AUTOSAR XML (schema 4-0-3)
standard types defined: Boolean, UInt16, UInt32, UInt8
package /AUTOSAR_Platform/DataConstrs
  range DC_Boolean: raw 0..1
  range DC_UInt16: raw 0..65535
  range DC_UInt8: raw 0..255
package /PATAC/MSM/ComponentTypes
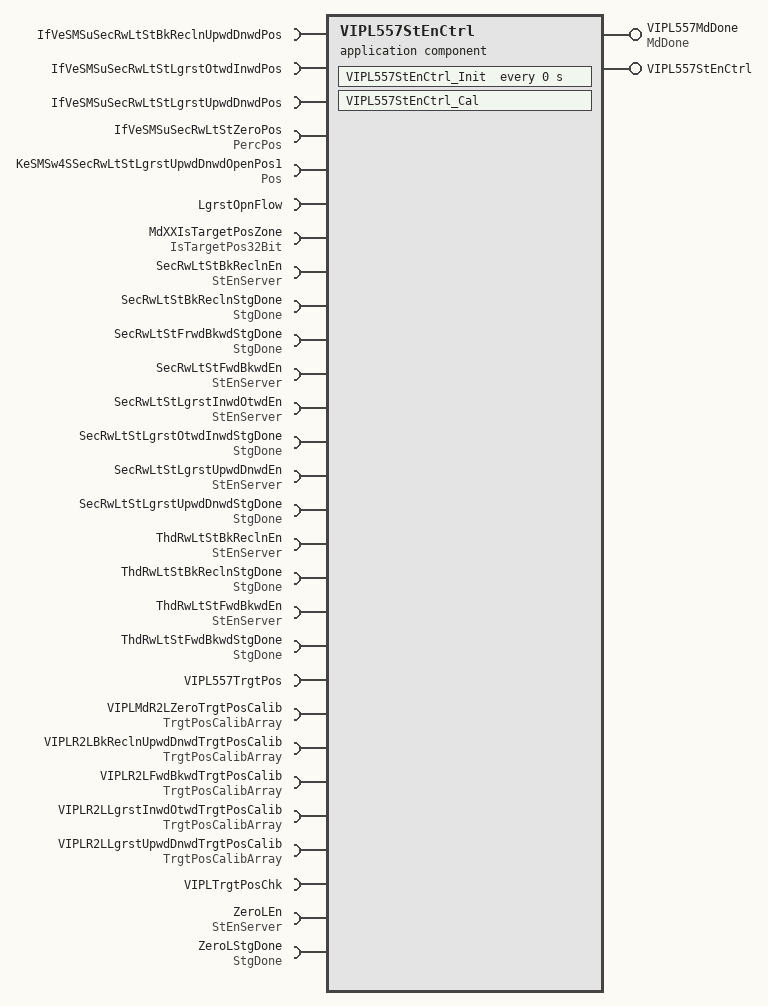
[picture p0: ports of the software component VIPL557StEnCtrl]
  application sw component type VIPL557StEnCtrl
    provide port VIPL557MdDone: nonqueued-sender-com-spec{data-element=MdDone/Val, init-value=0}, provided-interface=MdDone
    provide port VIPL557StEnCtrl: server-com-spec{operation=VIPL557StEnCtrl/Cal, queue-length=1}, provided-interface=VIPL557StEnCtrl
    28 x require port:
      IfVeSMSuSecRwLtStBkReclnUpwdDnwdPos: nonqueued-receiver-com-spec{data-element=IfVeSMSuSecRwLtStBkReclnUpwdDnwdPos/Val, filter=data-filter-type=ALWAYS, init-value=0}, required-interface=IfVeSMSuSecRwLtStBkReclnUpwdDnwdPos
      IfVeSMSuSecRwLtStLgrstOtwdInwdPos: nonqueued-receiver-com-spec{data-element=IfVeSMSuSecRwLtStLgrstOtwdInwdPos/Val, filter=data-filter-type=ALWAYS, init-value=0}, required-interface=IfVeSMSuSecRwLtStLgrstOtwdInwdPos
      IfVeSMSuSecRwLtStLgrstUpwdDnwdPos: nonqueued-receiver-com-spec{data-element=IfVeSMSuSecRwLtStLgrstUpwdDnwdPos/Val, filter=data-filter-type=ALWAYS, init-value=0}, required-interface=IfVeSMSuSecRwLtStLgrstUpwdDnwdPos
      IfVeSMSuSecRwLtStZeroPos: nonqueued-receiver-com-spec{data-element=PercPos/Val, filter=data-filter-type=ALWAYS, init-value=0}, required-interface=PercPos
      KeSMSw4SSecRwLtStLgrstUpwdDnwdOpenPos1: parameter-require-com-spec{init-value=0, parameter=Val}, required-interface=Pos
      LgrstOpnFlow: client-com-spec=LgrstOpnFlow/Cal, required-interface=LgrstOpnFlow
      MdXXIsTargetPosZone: nonqueued-receiver-com-spec{data-element=IsTargetPos32Bit/Val, filter=data-filter-type=ALWAYS, init-value=0}, required-interface=IsTargetPos32Bit
      SecRwLtStBkReclnEn: required-com-specs=[Clear, StEnServer/Get, StEnServer/Set], required-interface=StEnServer
      SecRwLtStBkReclnStgDone: nonqueued-receiver-com-spec{data-element=StgDone/Val, filter=data-filter-type=ALWAYS, init-value=0}, required-interface=StgDone
      SecRwLtStFrwdBkwdStgDone: nonqueued-receiver-com-spec{data-element=StgDone/Val, filter=data-filter-type=ALWAYS, init-value=0}, required-interface=StgDone
      SecRwLtStFwdBkwdEn: required-com-specs=[Clear, StEnServer/Get, StEnServer/Set], required-interface=StEnServer
      SecRwLtStLgrstInwdOtwdEn: required-com-specs=[Clear, StEnServer/Get, StEnServer/Set], required-interface=StEnServer
      SecRwLtStLgrstOtwdInwdStgDone: nonqueued-receiver-com-spec{data-element=StgDone/Val, filter=data-filter-type=ALWAYS, init-value=0}, required-interface=StgDone
      SecRwLtStLgrstUpwdDnwdEn: required-com-specs=[Clear, StEnServer/Get, StEnServer/Set], required-interface=StEnServer
      SecRwLtStLgrstUpwdDnwdStgDone: nonqueued-receiver-com-spec{data-element=StgDone/Val, filter=data-filter-type=ALWAYS, init-value=0}, required-interface=StgDone
      ThdRwLtStBkReclnEn: required-com-specs=[Clear, StEnServer/Get, StEnServer/Set], required-interface=StEnServer
      ThdRwLtStBkReclnStgDone: nonqueued-receiver-com-spec{data-element=StgDone/Val, filter=data-filter-type=ALWAYS, init-value=0}, required-interface=StgDone
      ThdRwLtStFwdBkwdEn: required-com-specs=[Clear, StEnServer/Get, StEnServer/Set], required-interface=StEnServer
      ThdRwLtStFwdBkwdStgDone: nonqueued-receiver-com-spec{data-element=StgDone/Val, filter=data-filter-type=ALWAYS, init-value=0}, required-interface=StgDone
      VIPL557TrgtPos: required-com-specs=[VIPL557TrgtPos/Get, VIPL557TrgtPos/Set], required-interface=VIPL557TrgtPos
      VIPLMdR2LZeroTrgtPosCalib: nonqueued-receiver-com-spec{data-element=TrgtPosArray, filter=data-filter-type=ALWAYS, init-value=[4095, 4095, 4095]}, required-interface=TrgtPosCalibArray
      VIPLR2LBkReclnUpwdDnwdTrgtPosCalib: nonqueued-receiver-com-spec{data-element=TrgtPosArray, filter=data-filter-type=ALWAYS, init-value=[4095, 4095, 4095]}, required-interface=TrgtPosCalibArray
      VIPLR2LFwdBkwdTrgtPosCalib: nonqueued-receiver-com-spec{data-element=TrgtPosArray, filter=data-filter-type=ALWAYS, init-value=[4095, 4095, 4095]}, required-interface=TrgtPosCalibArray
      VIPLR2LLgrstInwdOtwdTrgtPosCalib: nonqueued-receiver-com-spec{data-element=TrgtPosArray, filter=data-filter-type=ALWAYS, init-value=[4095, 4095, 4095]}, required-interface=TrgtPosCalibArray
      VIPLR2LLgrstUpwdDnwdTrgtPosCalib: nonqueued-receiver-com-spec{data-element=TrgtPosArray, filter=data-filter-type=ALWAYS, init-value=[4095, 4095, 4095]}, required-interface=TrgtPosCalibArray
      VIPLTrgtPosChk: client-com-spec=VIPLTrgtPosChk/Cal, required-interface=VIPLTrgtPosChk
      ZeroLEn: required-com-specs=[Clear, StEnServer/Get, StEnServer/Set], required-interface=StEnServer
      ZeroLStgDone: nonqueued-receiver-com-spec{data-element=StgDone/Val, filter=data-filter-type=ALWAYS, init-value=0}, required-interface=StgDone
    behavior VIPL557StEnCtrl_InternalBehavior
      operation invoked event OIT_VIPL557StEnCtrl_Cal_VIPL557StEnCtrl_Cal: start-on-event=VIPL557StEnCtrl_Cal, operation=VIPL557StEnCtrl.Cal
      timing event VIPL557StEnCtrl_InitEvent: start-on-event=VIPL557StEnCtrl_Init, period=0
      runnable VIPL557StEnCtrl_Cal
        data-receive-point-by-arguments:
          17 x access:
            REC_IfVeSMSuSecRwLtStBkReclnUpwdDnwdPos_Val: accessed-variable=IfVeSMSuSecRwLtStBkReclnUpwdDnwdPos.Val
            REC_IfVeSMSuSecRwLtStLgrstOtwdInwdPos_Val: accessed-variable=IfVeSMSuSecRwLtStLgrstOtwdInwdPos.Val
            REC_IfVeSMSuSecRwLtStLgrstUpwdDnwdPos_Val: accessed-variable=IfVeSMSuSecRwLtStLgrstUpwdDnwdPos.Val
            REC_IfVeSMSuSecRwLtStZeroPos_Val: accessed-variable=IfVeSMSuSecRwLtStZeroPos.Val
            REC_MdXXIsTargetPosZone_Val: accessed-variable=MdXXIsTargetPosZone.Val
            REC_SecRwLtStBkReclnStgDone_Val: accessed-variable=SecRwLtStBkReclnStgDone.Val
            REC_SecRwLtStFrwdBkwdStgDone_Val: accessed-variable=SecRwLtStFrwdBkwdStgDone.Val
            REC_SecRwLtStLgrstOtwdInwdStgDone_Val: accessed-variable=SecRwLtStLgrstOtwdInwdStgDone.Val
            REC_SecRwLtStLgrstUpwdDnwdStgDone_Val: accessed-variable=SecRwLtStLgrstUpwdDnwdStgDone.Val
            REC_ThdRwLtStBkReclnStgDone_Val: accessed-variable=ThdRwLtStBkReclnStgDone.Val
            REC_ThdRwLtStFwdBkwdStgDone_Val: accessed-variable=ThdRwLtStFwdBkwdStgDone.Val
            REC_VIPLMdR2LZeroTrgtPosCalib_TrgtPosArray: accessed-variable=VIPLMdR2LZeroTrgtPosCalib.TrgtPosArray
            REC_VIPLR2LBkReclnUpwdDnwdTrgtPosCalib_TrgtPosArray: accessed-variable=VIPLR2LBkReclnUpwdDnwdTrgtPosCalib.TrgtPosArray
            REC_VIPLR2LFwdBkwdTrgtPosCalib_TrgtPosArray: accessed-variable=VIPLR2LFwdBkwdTrgtPosCalib.TrgtPosArray
            REC_VIPLR2LLgrstInwdOtwdTrgtPosCalib_TrgtPosArray: accessed-variable=VIPLR2LLgrstInwdOtwdTrgtPosCalib.TrgtPosArray
            REC_VIPLR2LLgrstUpwdDnwdTrgtPosCalib_TrgtPosArray: accessed-variable=VIPLR2LLgrstUpwdDnwdTrgtPosCalib.TrgtPosArray
            REC_ZeroLStgDone_Val: accessed-variable=ZeroLStgDone.Val
        data-send-points:
          access SEND_VIPL557MdDone_Val: accessed-variable=VIPL557MdDone.Val
        parameter access PA_KeSMSw4SSecRwLtStLgrstUpwdDnwdOpenPos1_Val: accessed-parameter=KeSMSw4SSecRwLtStLgrstUpwdDnwdOpenPos1.Val
        17 x sync call, all with timeout=0:
          SC_LgrstOpnFlow_Cal: operation=LgrstOpnFlow.Cal
          SC_SecRwLtStBkReclnEn_Clear: operation=SecRwLtStBkReclnEn.Clear
          SC_SecRwLtStBkReclnEn_Set: operation=SecRwLtStBkReclnEn.Set
          SC_SecRwLtStFwdBkwdEn_Clear: operation=SecRwLtStFwdBkwdEn.Clear
          SC_SecRwLtStFwdBkwdEn_Set: operation=SecRwLtStFwdBkwdEn.Set
          SC_SecRwLtStLgrstInwdOtwdEn_Clear: operation=SecRwLtStLgrstInwdOtwdEn.Clear
          SC_SecRwLtStLgrstInwdOtwdEn_Set: operation=SecRwLtStLgrstInwdOtwdEn.Set
          SC_SecRwLtStLgrstUpwdDnwdEn_Clear: operation=SecRwLtStLgrstUpwdDnwdEn.Clear
          SC_SecRwLtStLgrstUpwdDnwdEn_Set: operation=SecRwLtStLgrstUpwdDnwdEn.Set
          SC_ThdRwLtStBkReclnEn_Clear: operation=ThdRwLtStBkReclnEn.Clear
          SC_ThdRwLtStBkReclnEn_Set: operation=ThdRwLtStBkReclnEn.Set
          SC_ThdRwLtStFwdBkwdEn_Clear: operation=ThdRwLtStFwdBkwdEn.Clear
          SC_ThdRwLtStFwdBkwdEn_Set: operation=ThdRwLtStFwdBkwdEn.Set
          SC_VIPL557TrgtPos_Get: operation=VIPL557TrgtPos.Get
          SC_VIPLTrgtPosChk_Cal: operation=VIPLTrgtPosChk.Cal
          SC_ZeroLEn_Clear: operation=ZeroLEn.Clear
          SC_ZeroLEn_Set: operation=ZeroLEn.Set
      runnable VIPL557StEnCtrl_Init
        parameter access PA_KeSMSw4SSecRwLtStLgrstUpwdDnwdOpenPos1_Val: accessed-parameter=KeSMSw4SSecRwLtStLgrstUpwdDnwdOpenPos1.Val
  swc implementation VIPL557StEnCtrl_Implementation: behavior=VIPL557StEnCtrl_InternalBehavior
    code-descriptors:
      code Default: artifact-descriptors=autosar-engineering-object={short-label=Default, category=SWSRC}
package /PATAC/MSM/Intervene/PortInterfaces
  client server interface VIPLTrgtPosChk  # PosAvl：1模式可用 PosAvl：0模式不可用
    operation Cal
      arg PosAvl: type=DataTypes/UInt8, direction=OUT, server-argument-impl-policy=USE-ARGUMENT-TYPE
package /PATAC/MSM/ModeAdjust/CalPortInterface
  parameter interface Pos
    parameter data prototype Val: sw-calibration-access=READ-WRITE, type=UInt16
package /PATAC/MSM/ModeAdjust/DataType
  impl type TrgtPosCalibArray: category=ARRAY, sw-calibration-access=READ-ONLY, type-emitter=RTE  # 0:pos 1:max 2:min
    element Element: array-size=3, array-size-semantics=FIXED-SIZE, implementation-data-type=UInt16, invalid-value=0
package /PATAC/MSM/ModeAdjust/PortInterface
  4 x client server interface:
    LgrstOpnFlow
      operation Cal
        9 x arg, all with server-argument-impl-policy=USE-ARGUMENT-TYPE:
          LgrstUpwdDnwdPos: type=UInt16, direction=IN
          LgrstUpwdDnwdOpenPos1: type=UInt16, direction=IN
          LgrstUpwdStgDone: type=Implementation/Boolean, direction=IN
          FtrstStgDone: type=Implementation/Boolean, direction=IN
          LgrstInwdStgDone: type=Implementation/Boolean, direction=IN
          Failflg: type=Implementation/Boolean, direction=OUT
          LgrstInwdOtwdEn: type=Implementation/Boolean, direction=OUT
          LgrstUpwdDnwdEn: type=Implementation/Boolean, direction=OUT
          FtrstEn: type=Implementation/Boolean, direction=OUT
    StEnServer
      operation Clear
        arg data: type=Implementation/UInt8, direction=IN, server-argument-impl-policy=USE-ARGUMENT-TYPE
      operation Get
        arg data: type=UInt32, direction=OUT, server-argument-impl-policy=USE-ARGUMENT-TYPE
      operation Set
        arg data: type=Implementation/UInt8, direction=IN, server-argument-impl-policy=USE-ARGUMENT-TYPE
    VIPL557StEnCtrl
      operation Cal
        arg FirstTrig: type=DataTypes/Boolean, direction=IN, server-argument-impl-policy=USE-ARGUMENT-TYPE
    VIPL557TrgtPos
      operation Get
        5 x arg, all with type=UInt16, direction=OUT, server-argument-impl-policy=USE-ARGUMENT-TYPE:
          SecRwLtStBkReclnTrgtPos
          SecRwLtStZeroTrgtPos
          SecRwLtStLgrstUpwdDnwdTrgtPos
          SecRwLtStLgrstInwdOtwdTrgtPos
          SecRwLtStFwdBkwdTrgtPos
      operation Set
        5 x arg, all with type=UInt16, direction=IN, server-argument-impl-policy=USE-ARGUMENT-TYPE:
          SecRwLtStBkReclnTrgtPos
          SecRwLtStZeroTrgtPos
          SecRwLtStLgrstUpwdDnwdTrgtPos
          SecRwLtStLgrstInwdOtwdTrgtPos
          SecRwLtStFwdBkwdTrgtPos
  5 x sender receiver interface:
    IsTargetPos32Bit: invalidation-policy{data-element=IsTargetPos32Bit/Val, handle-invalid=DONT-INVALIDATE}
      data Val: type=UInt32
    MdDone: invalidation-policy{data-element=MdDone/Val, handle-invalid=DONT-INVALIDATE}
      data Val: type=Implementation/UInt8
    PercPos: invalidation-policy{data-element=PercPos/Val, handle-invalid=DONT-INVALIDATE}
      data Val: type=UInt16
    StgDone: invalidation-policy{data-element=StgDone/Val, handle-invalid=DONT-INVALIDATE}
      data Val: type=Implementation/Boolean
    TrgtPosCalibArray: invalidation-policy{data-element=TrgtPosArray, handle-invalid=DONT-INVALIDATE}
      data TrgtPosArray: type=TrgtPosCalibArray  # 0:Pos 1:Max 2:Min
package /PATAC/MSM/PortInterfaces
  sender receiver interface IfVeSMSuSecRwLtStBkReclnUpwdDnwdPos: invalidation-policy{data-element=IfVeSMSuSecRwLtStBkReclnUpwdDnwdPos/Val, handle-invalid=DONT-INVALIDATE}
    data Val: type=UInt16
  sender receiver interface IfVeSMSuSecRwLtStLgrstOtwdInwdPos: invalidation-policy{data-element=IfVeSMSuSecRwLtStLgrstOtwdInwdPos/Val, handle-invalid=DONT-INVALIDATE}
    data Val: type=UInt16
  sender receiver interface IfVeSMSuSecRwLtStLgrstUpwdDnwdPos: invalidation-policy{data-element=IfVeSMSuSecRwLtStLgrstUpwdDnwdPos/Val, handle-invalid=DONT-INVALIDATE}
    data Val: type=UInt16
